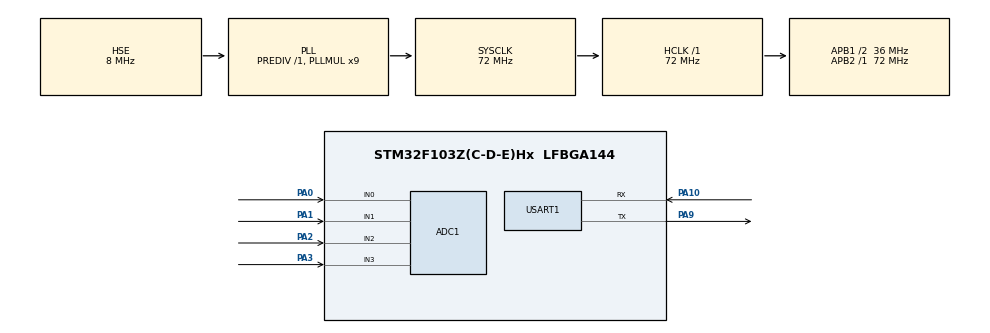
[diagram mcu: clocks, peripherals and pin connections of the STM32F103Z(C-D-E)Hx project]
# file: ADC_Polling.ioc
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ADC1.Channel-1\#ChannelRegularConversion=ADC_CHANNEL_0
ADC1.EnableAnalogWatchDog=false
ADC1.EnableRegularConversion=ENABLE
ADC1.InjNumberOfConversion=0
ADC1.NbrOfConversionFlag=1
ADC1.Rank-1\#ChannelRegularConversion=1
ADC1.SamplingTime-1\#ChannelRegularConversion=ADC_SAMPLETIME_1CYCLE_5
ADC1.master=1
Mcu.Family=STM32F1
Mcu.Name=STM32F103Z(C-D-E)Hx
Mcu.Package=LFBGA144
NVIC.PriorityGroup=NVIC_PRIORITYGROUP_4
OSC_IN.Mode=HSE-External-Oscillator
OSC_IN.Signal=RCC_OSC_IN
OSC_OUT.Mode=HSE-External-Oscillator
OSC_OUT.Signal=RCC_OSC_OUT
PA0-WKUP.Signal=ADCx_IN0
PA1.Signal=ADCx_IN1
PA10.Mode=Asynchronous
PA10.Signal=USART1_RX
PA13.Mode=JTAG_5_pin
PA13.Signal=SYS_JTMS-SWDIO
PA14.Mode=JTAG_5_pin
PA14.Signal=SYS_JTCK-SWCLK
PA15.Mode=JTAG_5_pin
PA15.Signal=SYS_JTDI
PA2.Signal=ADCx_IN2
PA3.Signal=ADCx_IN3
PA9.Mode=Asynchronous
PA9.Signal=USART1_TX
PB3.Mode=JTAG_5_pin
PB3.Signal=SYS_JTDO-TRACESWO
PB4.Mode=JTAG_5_pin
PB4.Signal=SYS_NJTRST
ProjectManager.TargetToolchain=MDK-ARM V5
RCC.ADCPresc=RCC_ADCPCLK2_DIV6
RCC.AHBFreq_Value=72000000
RCC.APB1CLKDivider=RCC_HCLK_DIV2
RCC.APB1Freq_Value=36000000
RCC.APB1TimFreq_Value=72000000
RCC.APB2Freq_Value=72000000
RCC.APB2TimFreq_Value=72000000
RCC.HCLKFreq_Value=72000000
RCC.HSIState=RCC_HSI_ON
RCC.PLLMUL=RCC_PLL_MUL9
RCC.PLLSourceVirtual=RCC_PLLSOURCE_HSE
RCC.SYSCLKFreq_VALUE=72000000
RCC.SYSCLKSource=RCC_SYSCLKSOURCE_PLLCLK
RCC.USBFreq_Value=72000000
SH.ADCx_IN0.0=ADC1_IN0,IN0
SH.ADCx_IN1.0=ADC1_IN1,IN1
SH.ADCx_IN2.0=ADC1_IN2,IN2
SH.ADCx_IN3.0=ADC1_IN3,IN3
board=ADC_Polling

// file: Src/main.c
/**
  ******************************************************************************
  * File Name          : main.c
  * Description        : Main program body
  ******************************************************************************
  *
  * COPYRIGHT(c) 2016 STMicroelectronics
  *
  * Redistribution and use in source and binary forms, with or without modification,
  * are permitted provided that the following conditions are met:
  *   1. Redistributions of source code must retain the above copyright notice,
  *      this list of conditions and the following disclaimer.
  *   2. Redistributions in binary form must reproduce the above copyright notice,
  *      this list of conditions and the following disclaimer in the documentation
  *      and/or other materials provided with the distribution.
  *   3. Neither the name of STMicroelectronics nor the names of its contributors
  *      may be used to endorse or promote products derived from this software
  *      without specific prior written permission.
  *
  * THIS SOFTWARE IS PROVIDED BY THE COPYRIGHT HOLDERS AND CONTRIBUTORS "AS IS"
  * AND ANY EXPRESS OR IMPLIED WARRANTIES, INCLUDING, BUT NOT LIMITED TO, THE
  * IMPLIED WARRANTIES OF MERCHANTABILITY AND FITNESS FOR A PARTICULAR PURPOSE ARE
  * DISCLAIMED. IN NO EVENT SHALL THE COPYRIGHT HOLDER OR CONTRIBUTORS BE LIABLE
  * FOR ANY DIRECT, INDIRECT, INCIDENTAL, SPECIAL, EXEMPLARY, OR CONSEQUENTIAL
  * DAMAGES (INCLUDING, BUT NOT LIMITED TO, PROCUREMENT OF SUBSTITUTE GOODS OR
  * SERVICES; LOSS OF USE, DATA, OR PROFITS; OR BUSINESS INTERRUPTION) HOWEVER
  * CAUSED AND ON ANY THEORY OF LIABILITY, WHETHER IN CONTRACT, STRICT LIABILITY,
  * OR TORT (INCLUDING NEGLIGENCE OR OTHERWISE) ARISING IN ANY WAY OUT OF THE USE
  * OF THIS SOFTWARE, EVEN IF ADVISED OF THE POSSIBILITY OF SUCH DAMAGE.
  *
  ******************************************************************************
  */
#include "stm32f1xx_hal.h"

/* USER CODE BEGIN Includes */
#include <stdio.h>
#include "ADC.h"
#include "UART.h"
/* USER CODE END Includes */

ADC_HandleTypeDef hadc1;

UART_HandleTypeDef huart1;

/* USER CODE BEGIN PV */
/* Private variables ---------------------------------------------------------*/

/* USER CODE END PV */

void SystemClock_Config(void);
static void MX_GPIO_Init(void);
static void MX_ADC1_Init(void);
static void MX_USART1_UART_Init(void);

/* USER CODE BEGIN PFP */
/* Private function prototypes -----------------------------------------------*/

/* USER CODE END PFP */

int main(void)
{

  /* MCU Configuration----------------------------------------------------------*/

  /* Reset of all peripherals, Initializes the Flash interface and the Systick. */
  HAL_Init();

  /* Configure the system clock */
  SystemClock_Config();

  /* Initialize all configured peripherals */
  MX_GPIO_Init();
  MX_ADC1_Init();
  MX_USART1_UART_Init();

  /* Infinite loop */
  while (1)
  {

  /* USER CODE BEGIN 3 */
		ADC_GetValue();
		printf("%d,%d,%d,%d\r\n",ADC_Value[0],ADC_Value[1],ADC_Value[2],ADC_Value[3]);
		HAL_Delay(500);
  }
  /* USER CODE END 3 */

}

/** System Clock Configuration
*/
void SystemClock_Config(void)
{

  RCC_OscInitTypeDef RCC_OscInitStruct;
  RCC_ClkInitTypeDef RCC_ClkInitStruct;
  RCC_PeriphCLKInitTypeDef PeriphClkInit;

  RCC_OscInitStruct.OscillatorType = RCC_OSCILLATORTYPE_HSE;
  RCC_OscInitStruct.HSEState = RCC_HSE_ON;
  RCC_OscInitStruct.HSEPredivValue = RCC_HSE_PREDIV_DIV1;
  RCC_OscInitStruct.PLL.PLLState = RCC_PLL_ON;
  RCC_OscInitStruct.PLL.PLLSource = RCC_PLLSOURCE_HSE;
  RCC_OscInitStruct.PLL.PLLMUL = RCC_PLL_MUL9;
  HAL_RCC_OscConfig(&RCC_OscInitStruct);

  RCC_ClkInitStruct.ClockType = RCC_CLOCKTYPE_SYSCLK|RCC_CLOCKTYPE_PCLK1;
  RCC_ClkInitStruct.SYSCLKSource = RCC_SYSCLKSOURCE_PLLCLK;
  RCC_ClkInitStruct.AHBCLKDivider = RCC_SYSCLK_DIV1;
  RCC_ClkInitStruct.APB1CLKDivider = RCC_HCLK_DIV2;
  RCC_ClkInitStruct.APB2CLKDivider = RCC_HCLK_DIV1;
  HAL_RCC_ClockConfig(&RCC_ClkInitStruct, FLASH_LATENCY_2);

  PeriphClkInit.PeriphClockSelection = RCC_PERIPHCLK_ADC;
  PeriphClkInit.AdcClockSelection = RCC_ADCPCLK2_DIV6;
  HAL_RCCEx_PeriphCLKConfig(&PeriphClkInit);

  HAL_SYSTICK_Config(HAL_RCC_GetHCLKFreq()/1000);

  HAL_SYSTICK_CLKSourceConfig(SYSTICK_CLKSOURCE_HCLK);

  /* SysTick_IRQn interrupt configuration */
  HAL_NVIC_SetPriority(SysTick_IRQn, 0, 0);
}

/* ADC1 init function */
void MX_ADC1_Init(void)
{

  ADC_ChannelConfTypeDef sConfig;

    /**Common config
    */
  hadc1.Instance = ADC1;
  hadc1.Init.ScanConvMode = ADC_SCAN_DISABLE;
  hadc1.Init.ContinuousConvMode = DISABLE;
  hadc1.Init.DiscontinuousConvMode = DISABLE;
  hadc1.Init.ExternalTrigConv = ADC_SOFTWARE_START;
  hadc1.Init.DataAlign = ADC_DATAALIGN_RIGHT;
  hadc1.Init.NbrOfConversion = 1;
  HAL_ADC_Init(&hadc1);

    /**Configure Regular Channel
    */
  sConfig.Channel = ADC_CHANNEL_0;
  sConfig.Rank = 1;
  sConfig.SamplingTime = ADC_SAMPLETIME_1CYCLE_5;
  HAL_ADC_ConfigChannel(&hadc1, &sConfig);

}

/* USART1 init function */
void MX_USART1_UART_Init(void)
{

  huart1.Instance = USART1;
  huart1.Init.BaudRate = 115200;
  huart1.Init.WordLength = UART_WORDLENGTH_8B;
  huart1.Init.StopBits = UART_STOPBITS_1;
  huart1.Init.Parity = UART_PARITY_NONE;
  huart1.Init.Mode = UART_MODE_TX_RX;
  huart1.Init.HwFlowCtl = UART_HWCONTROL_NONE;
  huart1.Init.OverSampling = UART_OVERSAMPLING_16;
  HAL_UART_Init(&huart1);

}

/** Configure pins as
        * Analog
        * Input
        * Output
        * EVENT_OUT
        * EXTI
*/
void MX_GPIO_Init(void)
{

  /* GPIO Ports Clock Enable */
  __GPIOB_CLK_ENABLE();
  __GPIOA_CLK_ENABLE();

}

/************************ (C) COPYRIGHT STMicroelectronics *****END OF FILE****/
